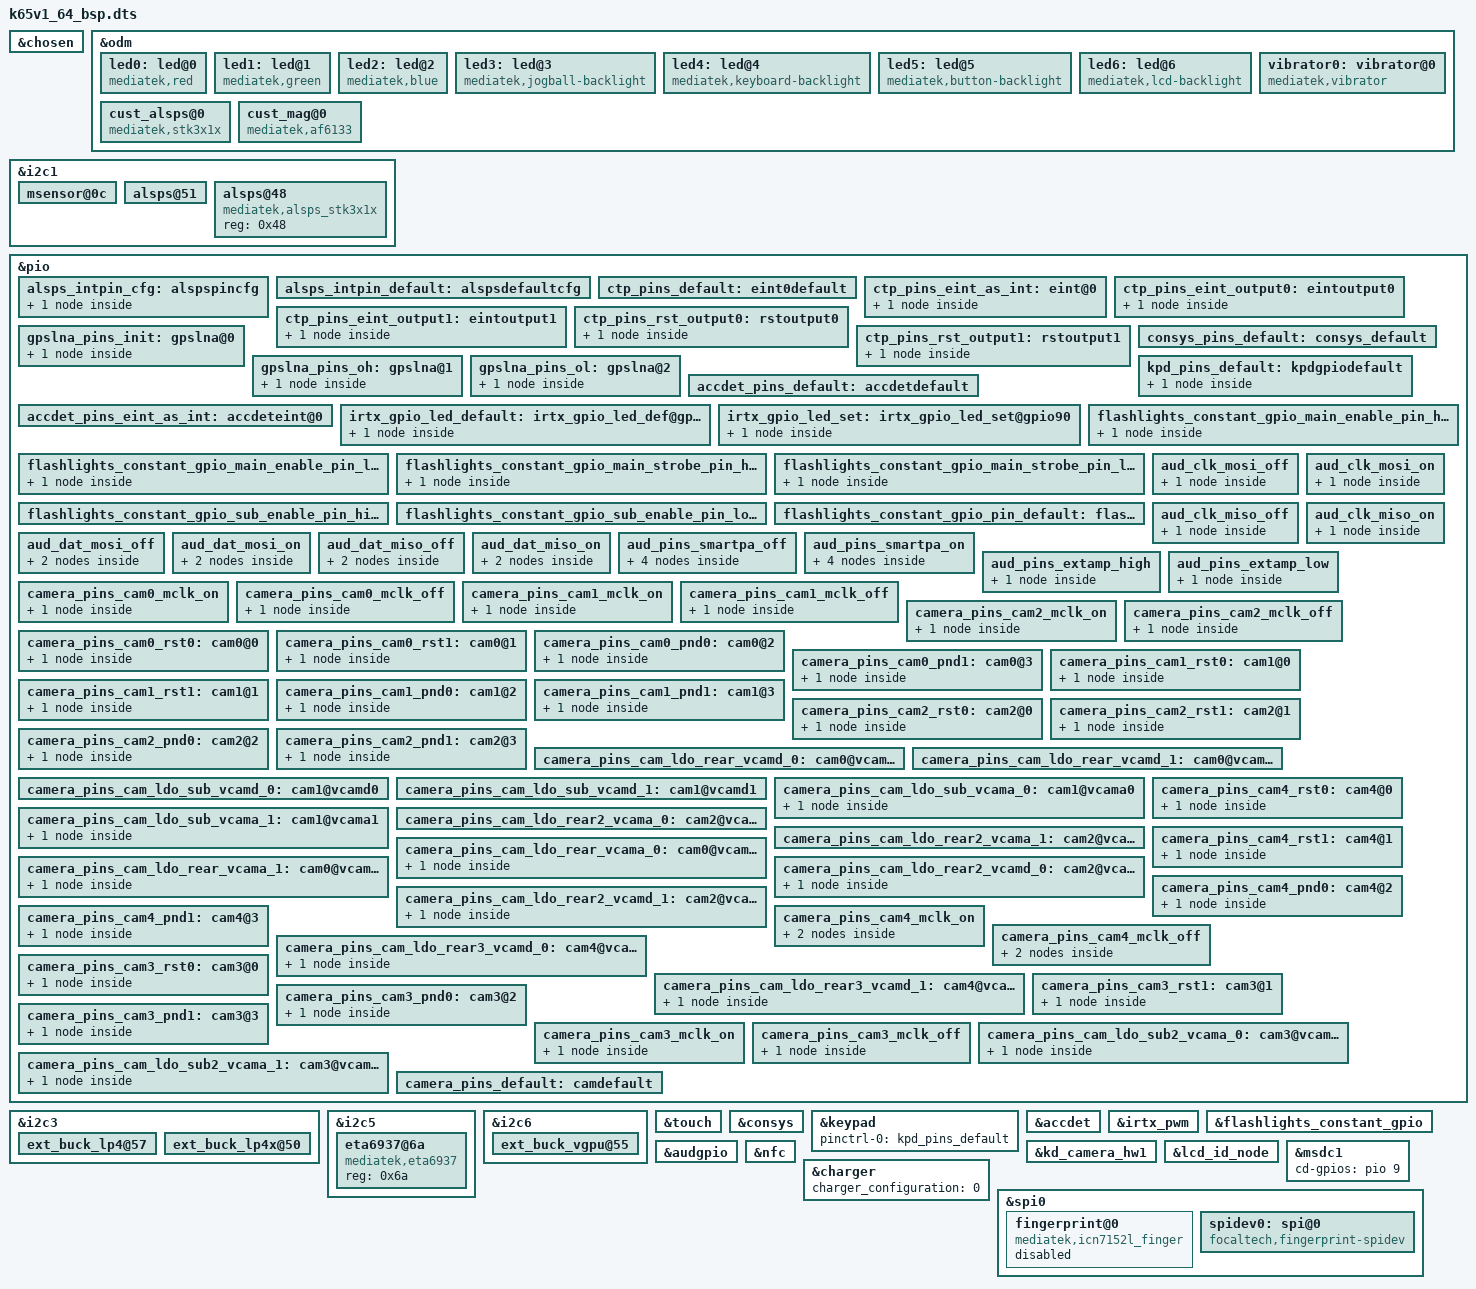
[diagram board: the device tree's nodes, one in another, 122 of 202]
// SPDX-License-Identifier: GPL-2.0+
/*
 * Copyright (c) 2019 MediaTek Inc.
 *
 */

#include <dt-bindings/interrupt-controller/arm-gic.h>
#include <dt-bindings/interrupt-controller/irq.h>
#include <dt-bindings/pinctrl/mt6765-pinfunc.h>
#include <dt-bindings/clock/mt6765-clk.h>

/dts-v1/;
/plugin/;

/* chosen */
&chosen {

	/* fpga may has no lk, we need to specify display info here */
	/* fb buffer is reserved using this dts by memory node above */
	atag,videolfb-fb_base_h = <0x0>;
	atag,videolfb-fb_base_l = <0x5e605000>;
	atag,videolfb-islcmfound = <1>;
	/* because no lk, so lcm is not inited */
	atag,videolfb-islcm_inited = <0>;
	atag,videolfb-fps= <6000>;
	atag,videolfb-vramSize= <0x017bb000>;
	atag,videolfb-lcmname= "nt35695B_fhd_dsi_cmd_auo_rt5081_drv";
};

&odm {
	led0:led@0 {
		compatible = "mediatek,red";
		led_mode = <0>;
		data = <1>;
		pwm_config = <0 0 0 0 0>;
	};
	led1:led@1 {
		compatible = "mediatek,green";
		led_mode = <0>;
		data = <1>;
		pwm_config = <0 0 0 0 0>;
	};
	led2:led@2 {
		compatible = "mediatek,blue";
		led_mode = <0>;
		data = <1>;
		pwm_config = <0 0 0 0 0>;
	};
	led3:led@3 {
		compatible = "mediatek,jogball-backlight";
		led_mode = <0>;
		data = <1>;
		pwm_config = <0 0 0 0 0>;
	};
	led4:led@4 {
		compatible = "mediatek,keyboard-backlight";
		led_mode = <0>;
		data = <1>;
		pwm_config = <0 0 0 0 0>;
	};
	led5:led@5 {
		compatible = "mediatek,button-backlight";
		led_mode = <0>;
		data = <1>;
		pwm_config = <0 0 0 0 0>;
	};
	led6:led@6 {
		compatible = "mediatek,lcd-backlight";
		led_mode = <5>;
		data = <1>;
		pwm_config = <0 3 0 0 0>;
	};
	vibrator0:vibrator@0 {
		compatible = "mediatek,vibrator";
		vib_timer = <25>;
		vib_limit = <9>;
		vib_vol= <9>;
	};
	
		cust_alsps@0 {
		compatible = "mediatek,stk3x1x";
		i2c_num	= <1>;
		i2c_addr = <0x48 0x00 0x00 0x00>;
		polling_mode_ps = <0>;
		polling_mode_als = <1>;
		power_id = <0xffff>;
		power_vol = <0>;//13 20 36 59 82 132 205
		als_level = <0 328 861 1377 3125 7721 7767 12621 23062 28430 33274 47116 57694 57694 65535>;
		als_value = <0 133 304 502 1004 2005 3058 5005 8008 10010 12000 16000 20000 20000 20000 20000>;
		ps_threshold_high		=  <1700>;
		ps_threshold_low		=  <1500>;
		is_batch_supported_ps	= <0>;
		is_batch_supported_als	= <0>;
	};
	
		cust_mag@0 {
		compatible			= "mediatek,af6133";
		i2c_num				= <1>;
		i2c_addr			= <0x0C 0 0 0>;
		direction			= <4>;
		power_id			= <0xffff>;
		power_vol			= <0>;
		is_batch_supported	= <0>;
	};
	
};


&i2c1 {
/*  start sensor */

	msensor@0c {
		i2c_num = <1>;
		i2c_addr = <0x0d 0 0 0>;
		direction = <8>;
		power_id = <0xffff>;
		power_vol = <0>;
		is_batch_supported = <0>;
	};
	
	alsps@51 {
		pinctrl-names = "pin_default", "pin_cfg";
		pinctrl-0 = <&alsps_intpin_default>;
		pinctrl-1 = <&alsps_intpin_cfg>;
		status = "okay";
		/* customization */
		i2c_num = <1>;
		i2c_addr = <0x51 0 0 0>;
		polling_mode_ps = <0>;
		polling_mode_als = <1>;
		power_id = <0xffff>;
		power_vol = <0>;
		als_level = <0 328 861 1377 3125 7721 7767 12621 23062 28430 33274 47116 57694 57694 65535>;
		als_value = <0 133 304 502 1004 2005 3058 5005 8008 10010 12000 16000 20000 20000 20000 20000>;
		ps_threshold_high = <26>;
		ps_threshold_low = <21>;
		is_batch_supported_ps = <0>;
		is_batch_supported_als = <0>;
	};


};

&i2c1 {
	alsps@48 {
		compatible = "mediatek,alsps_stk3x1x";
		reg = <0x48>;
		status = "okay";
	};
};

&pio {
	alsps_intpin_cfg: alspspincfg {

		pins_cmd_dat {
			pinmux = <PINMUX_GPIO6__FUNC_GPIO6>;
			//slew-rate = <input-enable>;
			input-enable;
			//slew-rate = <0>;
			bias-pull-up = <MTK_PUPD_SET_R1R0_01>;
		};
	};

	alsps_intpin_default: alspsdefaultcfg {

	};
};

&i2c3 {
	ext_buck_lp4@57 {
		regulator-name ="ext_buck_vdd2";
		regulator-min-microvolt = <300000>;
		regulator-max-microvolt = <1300000>;
		vsel_pin = <0>;
	};

	ext_buck_lp4x@50 {
		regulator-name ="ext_buck_vddq";
		regulator-min-microvolt = <300000>;
		regulator-max-microvolt = <1300000>;
		vsel_pin = <1>;
	};
};
/* eta6937 charger*/
&i2c5 {
	#address-cells = <1>;
	#size-cells = <0>;
	clock-frequency = <400000>;
	mediatek,use-open-drain;
	eta6937@6a {
		compatible = "mediatek,eta6937";
		reg = <0x6a>;
		status = "okay";
	};
};

&i2c6 {
	ext_buck_vgpu@55 {
		regulator-name ="ext_buck_vgpu";
		regulator-min-microvolt = <300000>;
		regulator-max-microvolt = <1300000>;
		vsel_pin = <2>;
	};
};
/* TOUCH start */
&touch {
	tpd-resolution = <720 1600>;
	use-tpd-button = <0>;
	tpd-key-num = <3>;
	tpd-key-local= <139 172 158 0>;
	tpd-key-dim-local = <90 883 100 40 230
				 883 100 40 370 883 100 40 0 0 0 0>;
	tpd-max-touch-num = <10>;
	tpd-filter-enable = <0>;
	tpd-filter-pixel-density = <146>;
	tpd-filter-custom-prameters = <0 0 0 0 0 0 0 0 0 0 0 0>;
	tpd-filter-custom-speed = <0 0 0>;
	touch,int-lead-gpio=<&pio 0 0>;
	pinctrl-names = "default", "state_eint_as_int", "state_eint_output0",
		"state_eint_output1", "state_rst_output0", "state_rst_output1";
	pinctrl-0 = <&ctp_pins_default>;
	pinctrl-1 = <&ctp_pins_eint_as_int>;
	pinctrl-2 = <&ctp_pins_eint_output0>;
	pinctrl-3 = <&ctp_pins_eint_output1>;
	pinctrl-4 = <&ctp_pins_rst_output0>;
	pinctrl-5 = <&ctp_pins_rst_output1>;
	status = "okay";
};
&pio {
	ctp_pins_default: eint0default {
	};
	ctp_pins_eint_as_int: eint@0 {
		pins_cmd_dat {
			pinmux = <PINMUX_GPIO0__FUNC_GPIO0>;
			slew-rate = <0>;
			bias-disable;
		};
	};
	ctp_pins_eint_output0: eintoutput0 {
		pins_cmd_dat {
			pinmux = <PINMUX_GPIO0__FUNC_GPIO0>;
			slew-rate = <1>;
			output-low;
		};
	};
	ctp_pins_eint_output1: eintoutput1 {
		pins_cmd_dat {
			pinmux = <PINMUX_GPIO0__FUNC_GPIO0>;
			slew-rate = <1>;
			output-high;
		};
	};
	ctp_pins_rst_output0: rstoutput0 {
		pins_cmd_dat {
			pinmux = <PINMUX_GPIO174__FUNC_GPIO174>;
			slew-rate = <1>;
			output-low;
		};
	};
	ctp_pins_rst_output1: rstoutput1 {
		pins_cmd_dat {
			pinmux = <PINMUX_GPIO174__FUNC_GPIO174>;
			slew-rate = <1>;
			output-high;
		};
	};
};
/* TOUCH end */

/* CONSYS GPIO standardization */
&pio {
	consys_pins_default: consys_default {
	};
	gpslna_pins_init: gpslna@0 {
		pins_cmd_dat {
			pinmux = <PINMUX_GPIO8__FUNC_GPIO8>;
			slew-rate = <0>;
			bias-disable;
			output-low;
		};
	};
	gpslna_pins_oh: gpslna@1 {
		pins_cmd_dat {
			pinmux = <PINMUX_GPIO8__FUNC_GPIO8>;
			slew-rate = <1>;
			output-high;
		};
	};
	gpslna_pins_ol: gpslna@2 {
		pins_cmd_dat {
			pinmux = <PINMUX_GPIO8__FUNC_GPIO8>;
			slew-rate = <1>;
			output-low;
		};
	};
};
&consys {
	pinctrl-names = "default", "gps_lna_state_init",
		"gps_lna_state_oh", "gps_lna_state_ol";
	pinctrl-0 = <&consys_pins_default>;
	pinctrl-1 = <&gpslna_pins_init>;
	pinctrl-2 = <&gpslna_pins_oh>;
	pinctrl-3 = <&gpslna_pins_ol>;
	status = "okay";
};
/* CONSYS end */

&keypad {
	pinctrl-names = "default";
	pinctrl-0 = <&kpd_pins_default>;
};

&pio {
	kpd_pins_default: kpdgpiodefault {
		pins_cmd_dat {
			pinmux = <PINMUX_GPIO93__FUNC_KPCOL0>;
			bias-pull-up = <MTK_PUPD_SET_R1R0_10>;
			output-low;
			input-schmitt-enable;
		};
	};
};


/* accdet start */
&accdet {
	accdet-mic-vol = <6>;
	headset-mode-setting = <0x500 0x500 1 0x1f0 0x800 0x800 0x20 0x44>;
	accdet-plugout-debounce = <1>;
	accdet-mic-mode = <1>;
	headset-eint-level-pol = <8>;
	headset-three-key-threshold = <0 80 220 400>;
	headset-three-key-threshold-CDD = <0 121 192 600>;
	headset-four-key-threshold = <0 58 121 192 400>;
	pinctrl-names = "default", "state_eint_as_int";
	pinctrl-0 = <&accdet_pins_default>;
	pinctrl-1 = <&accdet_pins_eint_as_int>;
	status = "okay";
};
&pio {
	accdet_pins_default: accdetdefault {
	};
	accdet_pins_eint_as_int: accdeteint@0 {

	};
};
/* accdet end */

// /* FINGERPRINT start */
// &spi0 {
// 	#address-cells = <1>;
// 	#size-cells = <0>;
// 	fingerprint@0 {
// 		compatible = "goodix,goodix-fp";
// 		reg = <0>;
// 		spi-max-frequency = <8000000>;
// 		netlink-event = <30>;
// 		status = "okay";
// 	};
// };

// &goodix_fp {
// 	pinctrl-names = "default", "reset_high", "reset_low";
// 	pinctrl-0 = <&fingerprint_default>;
// 	pinctrl-1 = <&fingerprint_reset_high>;
// 	pinctrl-2 = <&fingerprint_reset_low>;
// 	status = "okay";
// };

// &pio {
// 	fingerprint_default: state_default {
// 	};
// 	fingerprint_reset_high: state_reset_high {
// 		pins_cmd_dat {
// 			pinmux = <PINMUX_GPIO172__FUNC_GPIO172>;
// 			slew-rate = <1>;
// 			output-high;
// 		};
// 	};
// 	fingerprint_reset_low: state_reset_low {
// 		pins_cmd_dat {
// 			pinmux = <PINMUX_GPIO172__FUNC_GPIO172>;
// 			slew-rate = <1>;
// 			output-low;
// 		};
// 	};
// };
/* FINGERPRINT end */

/* IRTX GPIO end */
&irtx_pwm {
	pinctrl-names = "irtx_gpio_led_default", "irtx_gpio_led_set";
	pinctrl-0 = <&irtx_gpio_led_default>;
	pinctrl-1 = <&irtx_gpio_led_set>;
	status = "okay";
};
&pio {
	irtx_gpio_led_default:irtx_gpio_led_def@gpio90 {
		pins_cmd_dat {
			pinmux = <PINMUX_GPIO90__FUNC_GPIO90>;
			slew-rate = <1>;
			bias-disable;
			output-low;
			input-schmitt-enable = <0>;
		};
	};

	irtx_gpio_led_set:irtx_gpio_led_set@gpio90 {
		pins_cmd_dat {
			pinmux = <PINMUX_GPIO90__FUNC_PWM0>;
			slew-rate = <1>;
			output-high;
		};
	};
};
/* IRTX GPIO Settings -End */
&pio {
	flashlights_constant_gpio_main_enable_pin_high: main_enable_pin_high {
	    pins_cmd_dat {
			pinmux = <PINMUX_GPIO171__FUNC_GPIO171>;
			slew-rate = <1>;
			bias-disable;
			output-high;
		};
	};

	flashlights_constant_gpio_main_enable_pin_low: main_enable_pin_low {
	    pins_cmd_dat {
			pinmux = <PINMUX_GPIO171__FUNC_GPIO171>;
			slew-rate = <1>;
			bias-disable;
			output-low;
		};
	};

	flashlights_constant_gpio_main_strobe_pin_high: main_strobe_pin_high {
	    pins_cmd_dat {
			pinmux = <PINMUX_GPIO173__FUNC_GPIO173>;
			slew-rate = <1>;
			bias-disable;
			output-high;
		};
	};

	flashlights_constant_gpio_main_strobe_pin_low: main_strobe_pin_low {
	    pins_cmd_dat {
			pinmux = <PINMUX_GPIO173__FUNC_GPIO173>;
			slew-rate = <1>;
			bias-disable;
			output-low;
		};
	};

	flashlights_constant_gpio_sub_enable_pin_high: sub_enable_pin_high {

	};

	flashlights_constant_gpio_sub_enable_pin_low: sub_enable_pin_low {

	};

	flashlights_constant_gpio_pin_default: flashlight_defaultcfg {

	};
};

&flashlights_constant_gpio {
	pinctrl-names = "pin_default",
			"main_enable_pin_high", "main_enable_pin_low", "main_strobe_pin_high", "main_strobe_pin_low",
			"sub_enable_pin_high", "sub_enable_pin_low";
	pinctrl-0 = <&flashlights_constant_gpio_pin_default>;
	pinctrl-1 = <&flashlights_constant_gpio_main_enable_pin_high>;
	pinctrl-2 = <&flashlights_constant_gpio_main_enable_pin_low>;
	pinctrl-3 = <&flashlights_constant_gpio_main_strobe_pin_high>;
	pinctrl-4 = <&flashlights_constant_gpio_main_strobe_pin_low>;
	pinctrl-5 = <&flashlights_constant_gpio_sub_enable_pin_high>;
	pinctrl-6 = <&flashlights_constant_gpio_sub_enable_pin_low>;
	status = "okay";
};
/* xen 20180704 end */

/* AUDIO GPIO standardization */
&audgpio {
	pinctrl-names = "aud_clk_mosi_off",
			"aud_clk_mosi_on",
			"aud_clk_miso_off",
			"aud_clk_miso_on",
			"aud_dat_mosi_off",
			"aud_dat_mosi_on",
			"aud_dat_miso_off",
			"aud_dat_miso_on",
			"aud_smartpa_off",
			"aud_smartpa_on",
			"extamp-pullhigh",
			"extamp-pulllow";
	pinctrl-0 = <&aud_clk_mosi_off>;
	pinctrl-1 = <&aud_clk_mosi_on>;
	pinctrl-2 = <&aud_clk_miso_off>;
	pinctrl-3 = <&aud_clk_miso_on>;
	pinctrl-4 = <&aud_dat_mosi_off>;
	pinctrl-5 = <&aud_dat_mosi_on>;
	pinctrl-6 = <&aud_dat_miso_off>;
	pinctrl-7 = <&aud_dat_miso_on>;
	pinctrl-8 = <&aud_pins_smartpa_off>;
	pinctrl-9 = <&aud_pins_smartpa_on>;
	pinctrl-10 = <&aud_pins_extamp_high>;
	pinctrl-11 = <&aud_pins_extamp_low>;
	status = "okay";
};

&pio {
	aud_clk_mosi_off: aud_clk_mosi_off {
		pins_cmd0_dat {
			pinmux = <PINMUX_GPIO136__FUNC_GPIO136>;
		};
	};

	aud_clk_mosi_on: aud_clk_mosi_on {
		pins_cmd0_dat {
			pinmux = <PINMUX_GPIO136__FUNC_AUD_CLK_MOSI>;
		};
	};

	aud_clk_miso_off: aud_clk_miso_off {
		pins_cmd0_dat {
			pinmux = <PINMUX_GPIO140__FUNC_GPIO140>;
		};
	};

	aud_clk_miso_on: aud_clk_miso_on {
		pins_cmd0_dat {
			pinmux = <PINMUX_GPIO140__FUNC_AUD_CLK_MISO>;
		};
	};

	aud_dat_mosi_off: aud_dat_mosi_off {
		pins_cmd1_dat {
			pinmux = <PINMUX_GPIO138__FUNC_GPIO138>;
			input-enable;
			slew-rate = <0>;
			bias-disable;
		};
		pins_cmd2_dat {
			pinmux = <PINMUX_GPIO139__FUNC_GPIO139>;
			input-enable;
			slew-rate = <0>;
			bias-disable;
		};
	};

	aud_dat_mosi_on: aud_dat_mosi_on {
		pins_cmd1_dat {
			pinmux = <PINMUX_GPIO138__FUNC_AUD_DAT_MOSI0>;
		};
		pins_cmd2_dat {
			pinmux = <PINMUX_GPIO139__FUNC_AUD_DAT_MOSI1>;
		};
	};

	aud_dat_miso_off: aud_dat_miso_off {
		pins_cmd1_dat {
			pinmux = <PINMUX_GPIO142__FUNC_GPIO142>;
			input-enable;
			slew-rate = <0>;
			bias-disable;
		};
		pins_cmd2_dat {
			pinmux = <PINMUX_GPIO143__FUNC_GPIO143>;
			input-enable;
			slew-rate = <0>;
			bias-disable;
		};
	};

	aud_dat_miso_on: aud_dat_miso_on {
		pins_cmd1_dat {
			pinmux = <PINMUX_GPIO142__FUNC_AUD_DAT_MISO0>;
		};
		pins_cmd2_dat {
			pinmux = <PINMUX_GPIO143__FUNC_AUD_DAT_MISO1>;
		};
	};

	aud_pins_smartpa_off: aud_pins_smartpa_off {
		pins_cmd0_dat {
			pinmux = <PINMUX_GPIO17__FUNC_GPIO17>;
		};
		pins_cmd1_dat {
			pinmux = <PINMUX_GPIO18__FUNC_GPIO18>;
		};
		pins_cmd2_dat {
			pinmux = <PINMUX_GPIO19__FUNC_GPIO19>;
		};
		pins_cmd3_dat {
			pinmux = <PINMUX_GPIO20__FUNC_GPIO20>;
		};
	};

	aud_pins_smartpa_on: aud_pins_smartpa_on {
		pins_cmd0_dat {
			pinmux = <PINMUX_GPIO17__FUNC_I2S0_DI>;
		};
		pins_cmd1_dat {
			pinmux = <PINMUX_GPIO18__FUNC_I2S3_BCK>;
		};
		pins_cmd2_dat {
			pinmux = <PINMUX_GPIO19__FUNC_I2S3_LRCK>;
		};
		pins_cmd3_dat {
			pinmux = <PINMUX_GPIO20__FUNC_I2S3_DO>;
		};
	};
	aud_pins_extamp_high: aud_pins_extamp_high {
		pins_cmd_dat {
			pinmux = <PINMUX_GPIO159__FUNC_GPIO159>;
			slew-rate = <1>;
			output-high;
		};
	};

	aud_pins_extamp_low: aud_pins_extamp_low {
		pins_cmd_dat {
			pinmux = <PINMUX_GPIO159__FUNC_GPIO159>;
			slew-rate = <1>;
			output-low;
		};
	};
};
/* AUDIO end */

// &mt6370_pmu {
// 	mt6370,intr_gpio_num = <11>; /* direct defined GPIO num */
// 	mt6370,intr_gpio = <&pio 11 0x0>;
// };

// &mt6370_typec {
// 	mt6370pd,intr_gpio_num = <41>; /* direct defined GPIO num */
// 	mt6370pd,intr_gpio = <&pio 41 0x0>;
// };

// &mt6370_chg {
// 	bc12_sel = <1>;
// };

&pio {
	camera_pins_cam0_mclk_on: camera_pins_cam0_mclk_on {
		pins_cmd_dat {
			pinmux = <PINMUX_GPIO99__FUNC_CMMCLK0>;
		};
	};
	camera_pins_cam0_mclk_off: camera_pins_cam0_mclk_off {
		pins_cmd_dat {
			pinmux = <PINMUX_GPIO99__FUNC_GPIO99>;
		};
	};
	camera_pins_cam1_mclk_on: camera_pins_cam1_mclk_on {
		pins_cmd_dat {
			pinmux = <PINMUX_GPIO100__FUNC_CMMCLK1>;
		};
	};
	camera_pins_cam1_mclk_off: camera_pins_cam1_mclk_off {
		pins_cmd_dat {
			pinmux = <PINMUX_GPIO100__FUNC_GPIO100>;
		};
	};
	camera_pins_cam2_mclk_on: camera_pins_cam2_mclk_on {
		pins_cmd_dat {
			pinmux = <PINMUX_GPIO108__FUNC_CMMCLK2>;
		};
	};
	camera_pins_cam2_mclk_off: camera_pins_cam2_mclk_off {
		pins_cmd_dat {
			pinmux = <PINMUX_GPIO108__FUNC_GPIO108>;
		};
	};
	camera_pins_cam0_rst0: cam0@0 {
		pins_cmd_dat {
			pinmux = <PINMUX_GPIO101__FUNC_GPIO101>;
			slew-rate = <1>;
			output-low;
		};
	};
	camera_pins_cam0_rst1: cam0@1 {
		pins_cmd_dat {
			pinmux = <PINMUX_GPIO101__FUNC_GPIO101>;
			slew-rate = <1>;
			output-high;
		};
	};
	camera_pins_cam0_pnd0: cam0@2 {
		pins_cmd_dat {
			pinmux = <PINMUX_GPIO97__FUNC_GPIO97>;
			slew-rate = <1>;
			output-low;
		};
	};
	camera_pins_cam0_pnd1: cam0@3 {
		pins_cmd_dat {
			pinmux = <PINMUX_GPIO97__FUNC_GPIO97>;
			slew-rate = <1>;
			output-high;
		};
	};
	camera_pins_cam1_rst0: cam1@0 {
		pins_cmd_dat {
			pinmux = <PINMUX_GPIO102__FUNC_GPIO102>;
			slew-rate = <1>;
			output-low;
		};
	};
	camera_pins_cam1_rst1: cam1@1 {
		pins_cmd_dat {
			pinmux = <PINMUX_GPIO102__FUNC_GPIO102>;
			slew-rate = <1>;
			output-high;
		};
	};
	camera_pins_cam1_pnd0: cam1@2 {
		pins_cmd_dat {
			pinmux = <PINMUX_GPIO98__FUNC_GPIO98>;
			slew-rate = <1>;
			output-low;
		};
	};
	camera_pins_cam1_pnd1: cam1@3 {
		pins_cmd_dat {
			pinmux = <PINMUX_GPIO98__FUNC_GPIO98>;
			slew-rate = <1>;
			output-high;
		};
	};
	camera_pins_cam2_rst0: cam2@0 {
		pins_cmd_dat {
			pinmux = <PINMUX_GPIO109__FUNC_GPIO109>;
			slew-rate = <1>;
			output-low;
		};
	};
	camera_pins_cam2_rst1: cam2@1 {
		pins_cmd_dat {
			pinmux = <PINMUX_GPIO109__FUNC_GPIO109>;
			slew-rate = <1>;
			output-high;
		};
	};
	camera_pins_cam2_pnd0: cam2@2 {
		pins_cmd_dat {
			pinmux = <PINMUX_GPIO107__FUNC_GPIO107>;
			slew-rate = <1>;
			output-low;
		};
	};
	camera_pins_cam2_pnd1: cam2@3 {
		pins_cmd_dat {
			pinmux = <PINMUX_GPIO107__FUNC_GPIO107>;
			slew-rate = <1>;
			output-high;
		};
	};
	camera_pins_cam_ldo_rear_vcamd_0: cam0@vcamd0 {

	};
	camera_pins_cam_ldo_rear_vcamd_1: cam0@vcamd1 {

	};
	camera_pins_cam_ldo_sub_vcamd_0: cam1@vcamd0 {

	};
	camera_pins_cam_ldo_sub_vcamd_1: cam1@vcamd1 {

	};
	camera_pins_cam_ldo_sub_vcama_0: cam1@vcama0 {
		pins_cmd_dat {
			pinmux = <PINMUX_GPIO12__FUNC_GPIO12>;
			slew-rate = <1>;
			output-low;
		};
	};
	camera_pins_cam_ldo_sub_vcama_1: cam1@vcama1 {
		pins_cmd_dat {
			pinmux = <PINMUX_GPIO12__FUNC_GPIO12>;
			slew-rate = <1>;
			output-high;
		};
	};
	camera_pins_cam_ldo_rear2_vcama_0: cam2@vcama0 {

	};
	camera_pins_cam_ldo_rear2_vcama_1: cam2@vcama1 {

	};
	camera_pins_cam_ldo_rear_vcama_0: cam0@vcama0 {
		pins_cmd_dat {
			pinmux = <PINMUX_GPIO12__FUNC_GPIO12>;
			slew-rate = <1>;
			output-low;
		};
	};
	camera_pins_cam_ldo_rear_vcama_1: cam0@vcama1 {
		pins_cmd_dat {
			pinmux = <PINMUX_GPIO12__FUNC_GPIO12>;
			slew-rate = <1>;
			output-high;
		};
	};
	camera_pins_cam_ldo_rear2_vcamd_0: cam2@vcamd0 {
		pins_cmd_dat {
			pinmux = <PINMUX_GPIO167__FUNC_GPIO167>;
			slew-rate = <1>;
			output-low;
		};
	};
	camera_pins_cam_ldo_rear2_vcamd_1: cam2@vcamd1 {
		pins_cmd_dat {
			pinmux = <PINMUX_GPIO167__FUNC_GPIO167>;
			slew-rate = <1>;
			output-high;
		};
	};
	camera_pins_cam4_rst0: cam4@0 {
		pins_cmd_dat {
			pinmux = <PINMUX_GPIO164__FUNC_GPIO164>;
			slew-rate = <1>;
			output-low;
		};
	};
	camera_pins_cam4_rst1: cam4@1 {
		pins_cmd_dat {
			pinmux = <PINMUX_GPIO164__FUNC_GPIO164>;
			slew-rate = <1>;
			output-high;
		};
	};
	camera_pins_cam4_pnd0: cam4@2 {
		pins_cmd_dat {
			pinmux = <PINMUX_GPIO165__FUNC_GPIO165>;
			slew-rate = <1>;
			output-low;
		};
	};
	camera_pins_cam4_pnd1: cam4@3 {
		pins_cmd_dat {
			pinmux = <PINMUX_GPIO165__FUNC_GPIO165>;
			slew-rate = <1>;
			output-high;
		};
	};
	camera_pins_cam4_mclk_on: camera_pins_cam4_mclk_on {
		pins_cmd_dat {
			pinmux = <PINMUX_GPIO100__FUNC_CMMCLK1>;
		};
		pins_cmd_dat1 {
			pinmux = <PINMUX_GPIO175__FUNC_GPIO175>;
			slew-rate = <1>;
			output-low;
		};
	};
	camera_pins_cam4_mclk_off: camera_pins_cam4_mclk_off {
		pins_cmd_dat {
			pinmux = <PINMUX_GPIO100__FUNC_GPIO100>;
		};
		pins_cmd_dat1 {
			pinmux = <PINMUX_GPIO175__FUNC_GPIO175>;
			slew-rate = <1>;
			output-low;
		};
	};
	camera_pins_cam_ldo_rear3_vcamd_0: cam4@vcamd0 {
		pins_cmd_dat {
			pinmux = <PINMUX_GPIO167__FUNC_GPIO167>;
			slew-rate = <1>;
			output-low;
		};
	};
	camera_pins_cam_ldo_rear3_vcamd_1: cam4@vcamd1 {
		pins_cmd_dat {
			pinmux = <PINMUX_GPIO167__FUNC_GPIO167>;
			slew-rate = <1>;
			output-high;
		};
	};	
	camera_pins_cam3_rst0: cam3@0 {
		pins_cmd_dat {
			pinmux = <PINMUX_GPIO87__FUNC_GPIO87>;
			slew-rate = <1>;
			output-low;
		};
	};
	camera_pins_cam3_rst1: cam3@1 {
		pins_cmd_dat {
			pinmux = <PINMUX_GPIO87__FUNC_GPIO87>;
			slew-rate = <1>;
			output-high;
		};
	};
	camera_pins_cam3_pnd0: cam3@2 {
		pins_cmd_dat {
			pinmux = <PINMUX_GPIO160__FUNC_GPIO160>;
			slew-rate = <1>;
			output-low;
		};
	};
	camera_pins_cam3_pnd1: cam3@3 {
		pins_cmd_dat {
			pinmux = <PINMUX_GPIO160__FUNC_GPIO160>;
			slew-rate = <1>;
			output-high;
		};
	};
	camera_pins_cam3_mclk_on: camera_pins_cam3_mclk_on {
		pins_cmd_dat {
			pinmux = <PINMUX_GPIO88__FUNC_CMMCLK3>;
		};
	};
	camera_pins_cam3_mclk_off: camera_pins_cam3_mclk_off {
		pins_cmd_dat {
			pinmux = <PINMUX_GPIO88__FUNC_GPIO88>;
		};
	};
	camera_pins_cam_ldo_sub2_vcama_0: cam3@vcama0 {
		pins_cmd_dat {
			pinmux = <PINMUX_GPIO10__FUNC_GPIO10>;
			slew-rate = <1>;
			output-low;
		};
	};
	camera_pins_cam_ldo_sub2_vcama_1: cam3@vcama1 {
		pins_cmd_dat {
			pinmux = <PINMUX_GPIO10__FUNC_GPIO10>;
			slew-rate = <1>;
			output-high;
		};
	};	
	camera_pins_default: camdefault {
	};
};

&kd_camera_hw1 {
	pinctrl-names = "default",
			"cam0_rst0",
			"cam0_rst1",
			"cam0_pnd0",
			"cam0_pnd1",
			"cam1_rst0",
			"cam1_rst1",
			"cam1_pnd0",
			"cam1_pnd1",
			"cam2_rst0",
			"cam2_rst1",
			"cam2_pnd0",
			"cam2_pnd1",
			"cam0_vcamd_on",
			"cam0_vcamd_off",
			"cam1_vcamd_on",
			"cam1_vcamd_off",
			"cam1_vcama_on",
			"cam1_vcama_off",
			"cam2_vcama_on",
			"cam2_vcama_off",
			"cam0_mclk_on",
			"cam0_mclk_off",
			"cam1_mclk_on",
			"cam1_mclk_off",
			"cam2_mclk_on",
			"cam2_mclk_off",
			"cam0_vcama_on",
			"cam0_vcama_off",
			"cam2_vcamd_on",
			"cam2_vcamd_off",
			"cam4_rst0",
			"cam4_rst1",
			"cam4_pnd0",
			"cam4_pnd1",
			"cam4_mclk_on",
			"cam4_mclk_off",
			"cam4_vcamd_on",
			"cam4_vcamd_off",
			"cam3_rst0",
			"cam3_rst1",
			"cam3_pnd0",
			"cam3_pnd1",
			"cam3_mclk_on",
			"cam3_mclk_off",
			"cam3_vcama_on",
			"cam3_vcama_off";

	pinctrl-0 = <&camera_pins_default>;
	pinctrl-1 = <&camera_pins_cam0_rst0>;
	pinctrl-2 = <&camera_pins_cam0_rst1>;
	pinctrl-3 = <&camera_pins_cam0_pnd0>;
	pinctrl-4 = <&camera_pins_cam0_pnd1>;
	pinctrl-5 = <&camera_pins_cam1_rst0>;
	pinctrl-6 = <&camera_pins_cam1_rst1>;
	pinctrl-7 = <&camera_pins_cam1_pnd0>;
	pinctrl-8 = <&camera_pins_cam1_pnd1>;
	pinctrl-9 = <&camera_pins_cam2_rst0>;
	pinctrl-10 = <&camera_pins_cam2_rst1>;
	pinctrl-11 = <&camera_pins_cam2_pnd0>;
	pinctrl-12 = <&camera_pins_cam2_pnd1>;
	pinctrl-13 = <&camera_pins_cam_ldo_rear_vcamd_1>;
	pinctrl-14 = <&camera_pins_cam_ldo_rear_vcamd_0>;
	pinctrl-15 = <&camera_pins_cam_ldo_sub_vcamd_1>;
	pinctrl-16 = <&camera_pins_cam_ldo_sub_vcamd_0>;
	pinctrl-17 = <&camera_pins_cam_ldo_sub_vcama_1>;
	pinctrl-18 = <&camera_pins_cam_ldo_sub_vcama_0>;
	pinctrl-19 = <&camera_pins_cam_ldo_rear2_vcama_1>;
	pinctrl-20 = <&camera_pins_cam_ldo_rear2_vcama_0>;
	pinctrl-21 = <&camera_pins_cam0_mclk_on>;
	pinctrl-22 = <&camera_pins_cam0_mclk_off>;
	pinctrl-23 = <&camera_pins_cam1_mclk_on>;
	pinctrl-24 = <&camera_pins_cam1_mclk_off>;
	pinctrl-25 = <&camera_pins_cam2_mclk_on>;
	pinctrl-26 = <&camera_pins_cam2_mclk_off>;
	pinctrl-27 = <&camera_pins_cam_ldo_rear_vcama_1>;
	pinctrl-28 = <&camera_pins_cam_ldo_rear_vcama_0>;
	pinctrl-29 = <&camera_pins_cam_ldo_rear2_vcamd_1>;
	pinctrl-30 = <&camera_pins_cam_ldo_rear2_vcamd_0>;
	pinctrl-31 = <&camera_pins_cam4_rst0>;
	pinctrl-32 = <&camera_pins_cam4_rst1>;
	pinctrl-33 = <&camera_pins_cam4_pnd0>;
	pinctrl-34 = <&camera_pins_cam4_pnd1>;
	pinctrl-35 = <&camera_pins_cam4_mclk_on>;
	pinctrl-36 = <&camera_pins_cam4_mclk_off>;
	pinctrl-37 = <&camera_pins_cam_ldo_rear3_vcamd_1>;
	pinctrl-38 = <&camera_pins_cam_ldo_rear3_vcamd_0>;
	pinctrl-39 = <&camera_pins_cam3_rst0>;
	pinctrl-40 = <&camera_pins_cam3_rst1>;
	pinctrl-41 = <&camera_pins_cam3_pnd0>;
	pinctrl-42 = <&camera_pins_cam3_pnd1>;
	pinctrl-43 = <&camera_pins_cam3_mclk_on>;
	pinctrl-44 = <&camera_pins_cam3_mclk_off>;
	pinctrl-45 = <&camera_pins_cam_ldo_sub2_vcama_1>;
	pinctrl-46 = <&camera_pins_cam_ldo_sub2_vcama_0>;
	
	cam0_vcamd-supply = <&mt_pmic_vcamd_ldo_reg>;
	cam1_vcamd-supply = <&mt_pmic_vcamd_ldo_reg>;
	cam2_vcamd-supply = <&mt_pmic_vcamd_ldo_reg>;
	cam3_vcamd-supply = <&mt_pmic_vcamd_ldo_reg>;
	cam4_vcamd-supply = <&mt_pmic_vcamd_ldo_reg>;
	cam0_vcamio-supply = <&mt_pmic_vcamio_ldo_reg>;
	cam1_vcamio-supply = <&mt_pmic_vcamio_ldo_reg>;
	cam2_vcamio-supply = <&mt_pmic_vcamio_ldo_reg>;
	cam3_vcamio-supply = <&mt_pmic_vcamio_ldo_reg>;
	cam4_vcamio-supply = <&mt_pmic_vcamio_ldo_reg>;
	cam0_vcama-supply = <&mt_pmic_vcama_ldo_reg>;
	cam1_vcama-supply = <&mt_pmic_vcama_ldo_reg>;
	cam2_vcama-supply = <&mt_pmic_vcama_ldo_reg>;
	cam3_vcama-supply = <&mt_pmic_vcama_ldo_reg>;
	cam4_vcama-supply = <&mt_pmic_vcama_ldo_reg>;
	status = "okay";
};
&lcd_id_node {
    gpio_lcd_id = <&pio 3 0>;
    gpio_lcm_enp = <&pio 150 0>;
    gpio_lcm_enn = <&pio 153 0>;
    gpio_tp_reset = <&pio 174 0>;
    gpio_charge_en = <&pio 76 0>;
};

&nfc{
	gpio-rst = <172>;
	gpio-rst-std = <&pio 172 0x0>;
	gpio-irq = <1>;
	gpio-irq-std = <&pio 1 0x0>;
};


&msdc1 {
	cd-gpios = <&pio 9 0>;
};
&charger {
	charger_configuration= <0>;
};
/* FINGERPRINT start */
&spi0 {
	#address-cells = <1>;
	#size-cells = <0>;
	fingerprint@0 {
		compatible = "mediatek,icn7152l_finger";   
		reg = <0>;
		spi-max-frequency = <8000000>;
		netlink-event = <30>;
		status = "disabled";
	};

	  spidev0: spi@0 {
          compatible = "focaltech,fingerprint-spidev";
          reg = <0>;
          spi-max-frequency = <1000000>;
          fingerprint,touch-int-gpio = <&pio 4 0>;
        //   fingerprint,en-gpio = <&pio 3 0>;   //power
          status = "okay";
	  };
};

/* FINGERPRINT end */
#include "mediatek/fpsensor.dtsi"
#include "k65v1_64_bsp/cust.dtsi"
//#include "mediatek/cust_mt6765_camera.dtsi"
//#include "mediatek/cust_mt6765_touch_1080x1920.dtsi"
/*End of this file, DO NOT ADD ANYTHING HERE*/
